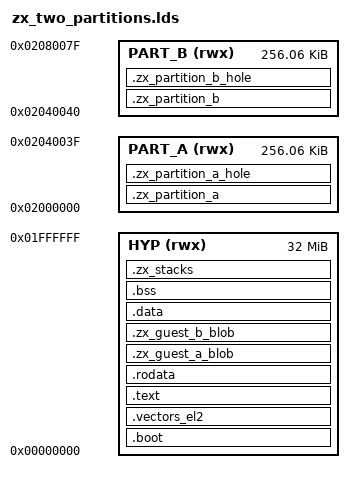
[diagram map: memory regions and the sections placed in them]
/***************************************************************************
 * Copyright (c) 2026 Eclipse ThreadX contributors
 *
 * This program and the accompanying materials are made available under the
 * terms of the MIT License which is available at
 * https://opensource.org/licenses/MIT.
 *
 * AI Disclosure: This file was largely AI-generated by Claude Code (Opus 5).
 * The AI-generated portions may be considered public domain (CC0-1.0)
 * and not subject to the project's licence. The human contributor has
 * reviewed and verified that the code is correct.
 *
 * SPDX-License-Identifier: MIT and CC0-1.0
 **************************************************************************/

/* Link map for the ZoneX TWO-PARTITION image on the Armv8-R AEM FVP.
 *
 * WHY THIS IS A THIRD SCRIPT AND NOT AN EXTENSION OF THE OTHER TWO
 *
 * The three images describe genuinely different memory.  The stage-2 probe
 * has two small windows and a relocatable blob copied into both; the
 * one-partition image has a single 256 KB window and embeds one guest; this
 * one has TWO 256 KB windows and embeds two, because a guest is linked for
 * its window and two windows are two different sets of bytes.
 *
 * Sharing one script would mean an image carrying a KEEP for a section it
 * never supplies -- which produces an EMPTY section rather than an error,
 * silently, at whatever address the location counter held.  That is the exact
 * failure the loader's magic-number check exists to catch, and the right
 * place to avoid it is here.
 *
 * THE WINDOW ADDRESSES ARE A CONTRACT, NOT A CHOICE.  Each is passed to its
 * guest's build from examples/fvp_baser_aemv8r/CMakeLists.txt, which is the
 * one place they are written down, and each guest declares what it was built
 * for in its own image header so that a mismatch is REFUSED at boot rather
 * than discovered as a fault at a plausible-looking address.  The numbers
 * below have to agree with that file, and the ASSERTs at the foot of this
 * script are what say so.
 *
 * THE UNGRANTED GRANULE BETWEEN THE TWO WINDOWS IS LOAD-BEARING.  Sixty-four
 * bytes belonging to nobody sit immediately after partition A and
 * immediately before partition B.  A region limit one granule too generous
 * at either end reaches into it, and an access there must fault -- which is
 * why partition B's base is not a round number.  An ungranted address far
 * from every grant proves only that unmapped memory faults; adjacency is
 * what makes it a boundary test.
 *
 * A NOTE ON ALIGN, because the two spellings are not equivalent
 *
 * Every ALIGN below is written AFTER the colon, which is the section's
 * ALIGNMENT.  Written before the colon it is the section's ADDRESS,
 * evaluated from a location counter that starts at zero, and it silently
 * overrides the region assignment.  Harmless where memory starts at zero and
 * catastrophic where it does not -- which is what makes it worth repeating
 * in every script here rather than in one of them.
 *
 * ZoneX's OWN code, data, bss and stack are covered by no region at all.
 * That is decision D2: with HSCTLR.BR=1 EL2's own accesses fall back to the
 * background map, while EL0/EL1 accesses that hit no region fault regardless
 * of BR -- so the hypervisor costs no region and is protected from the guest
 * precisely by not being mapped.
 */

ENTRY(_start)

__zx_hyp_stack_size = 0x1000;

/* THE PARTITION WINDOWS.  Each pair is passed to its guest's build from this
   board's CMakeLists.txt, and checked at boot against the guest's own image
   header.  */

__zx_partition_a_base = 0x02000000;
__zx_partition_a_size = 0x00040000;
__zx_partition_b_base = 0x02040040;
__zx_partition_b_size = 0x00040000;

MEMORY
{
    /* Two regions rather than one location counter, so that the window's
       address is declared rather than arrived at.  A script that reached
       0x02000000 by assignment would place the window correctly today and
       silently move it the first time the hypervisor's own image grew past
       32 MB -- which is a change nobody would connect to a guest that
       stopped working.  */

    HYP    (rwx) : ORIGIN = 0x00000000, LENGTH = 0x02000000    /* 32 MB    */
    PART_A (rwx) : ORIGIN = 0x02000000, LENGTH = 0x00040040    /* + a hole */
    PART_B (rwx) : ORIGIN = 0x02040040, LENGTH = 0x00040040    /* + a hole */
}

SECTIONS
{
    . = ALIGN(64);

    .boot :
    {
        KEEP(*(.text.boot))
    } > HYP

    .vectors_el2 :
    {
        KEEP(*(.vectors_el2))
    } > HYP

    .text :
    {
        *(.text*)
        *(.glue_7)
        *(.glue_7t)
    } > HYP

    .rodata :
    {
        . = ALIGN(4);
        *(.rodata*)
        . = ALIGN(4);
    } > HYP

    /* ------------------------------------------------------------------
       THE GUEST IMAGE, in the hypervisor's own memory.

       Covered by no stage-2 region, exactly like the rest of ZoneX, so a
       running partition cannot read the image it was loaded from -- which
       matters more than it looks: a partition able to read its own source
       image could also read the NEXT partition's, and the isolation claim
       would be about the copies rather than about the originals.
       ------------------------------------------------------------------ */

    .zx_guest_a_blob : ALIGN(64)
    {
        __zx_guest_a_blob_start = .;
        KEEP(*(.zx_guest_a_blob))
        . = ALIGN(4);
        __zx_guest_a_blob_end = .;
    } > HYP

    .zx_guest_b_blob : ALIGN(64)
    {
        __zx_guest_b_blob_start = .;
        KEEP(*(.zx_guest_b_blob))
        . = ALIGN(4);
        __zx_guest_b_blob_end = .;
    } > HYP

    .data : ALIGN(64)
    {
        __zx_data_start = .;
        *(.data*)
        . = ALIGN(4);
        __zx_data_end = .;
    } > HYP

    .bss (NOLOAD) : ALIGN(64)
    {
        __zx_bss_start = .;
        *(.bss*)
        *(COMMON)
        . = ALIGN(4);
        __zx_bss_end = .;
    } > HYP

    /* SP must stay 8-byte aligned (AAPCS), so the area is aligned before
       its top symbol is taken.  */

    .zx_stacks (NOLOAD) :
    {
        . = ALIGN(8);
        . = . + __zx_hyp_stack_size;
        __zx_hyp_stack_top = .;
    } > HYP

    . = ALIGN(8);
    _end = .;
    PROVIDE(end = .);

    /* ------------------------------------------------------------------
       PARTITION A'S WINDOW, and the ungranted granule after it.

       NOLOAD: there is nothing in this ELF to load here.  The contents
       arrive at run time, when the loader copies the guest image in, which
       is the path a real guest takes and the reason the manifest's
       image_start and image_end are load-bearing rather than decorative.

       THE HOLE IS ADJACENT BY CONSTRUCTION and the ASSERT keeps it that
       way.  An ungranted address far from every grant proves only that
       unmapped memory faults; the defect class worth catching is a region
       whose limit is out by ONE GRANULE, and only an adjacent hole catches
       it.
       ------------------------------------------------------------------ */

    .zx_partition_a (NOLOAD) : ALIGN(64)
    {
        __zx_partition_a_start = .;
        . = . + __zx_partition_a_size;
        __zx_partition_a_end = .;
    } > PART_A

    .zx_partition_a_hole (NOLOAD) : ALIGN(64)
    {
        __zx_partition_a_hole_start = .;
        . = . + 64;
        __zx_partition_a_hole_end = .;
    } > PART_A

    /* ------------------------------------------------------------------
       PARTITION B'S WINDOW, and its own ungranted granule.

       B's base is A's hole's END, so the sixty-four bytes between them
       belong to neither partition and are adjacent to both.  That single
       granule is what catches a limit one granule too generous at EITHER
       end -- the defect class that otherwise reads as a working system,
       because two region sets a whole kilobyte apart would pass a test
       that only checked the neighbour's data.
       ------------------------------------------------------------------ */

    .zx_partition_b (NOLOAD) : ALIGN(64)
    {
        __zx_partition_b_start = .;
        . = . + __zx_partition_b_size;
        __zx_partition_b_end = .;
    } > PART_B

    .zx_partition_b_hole (NOLOAD) : ALIGN(64)
    {
        __zx_partition_b_hole_start = .;
        . = . + 64;
        __zx_partition_b_hole_end = .;
    } > PART_B

    /* ------------------------------------------------------------------
       Assert the geometry the region programming and the loader depend on,
       so that a layout mistake fails the LINK rather than the run.  A
       region whose base is under-aligned does not fault: its low bits land
       on SH, AP and XN and silently change what it grants, which is the
       single hardest failure in this architecture to see.
       ------------------------------------------------------------------ */

    ASSERT((__zx_partition_a_start & 63) == 0,
           "partition A's window base is not 64-byte aligned")
    ASSERT((__zx_partition_a_end & 63) == 0,
           "partition A's window is not a whole number of granules")
    ASSERT(__zx_partition_a_start == __zx_partition_a_base,
           "partition A's window is not at the address the guest was linked for")
    ASSERT(__zx_partition_a_hole_start == __zx_partition_a_end,
           "the ungranted granule is NOT adjacent to partition A's window")

    ASSERT((__zx_partition_b_start & 63) == 0,
           "partition B's window base is not 64-byte aligned")
    ASSERT(((__zx_partition_b_end - __zx_partition_b_start) & 63) == 0,
           "partition B's window is not a whole number of granules")
    ASSERT(__zx_partition_b_start == __zx_partition_b_base,
           "partition B's window is not at the address its guest was linked for")
    ASSERT(__zx_partition_b_hole_start == __zx_partition_b_end,
           "the ungranted granule is NOT adjacent to partition B's window")

    /* AND THE GRANULE BETWEEN THEM BELONGS TO NOBODY.  A's hole ends
       exactly where B's window begins, so there is one ungranted granule
       and it is adjacent to both windows.  Written as an assert rather than
       trusted to the MEMORY lengths, because the two are computed from
       different numbers and a change to either would break this silently.  */

    ASSERT(__zx_partition_a_hole_end == __zx_partition_b_start,
           "the ungranted granule is not adjacent to both partition windows")

    /* And the two windows do not overlap, which PMSAv8-R makes worse than a
       logical error: two enabled regions matching one address is CONSTRAINED
       UNPREDICTABLE, and it aborts on the S32Z280.  The manifest validator
       refuses it too; this catches it a whole build earlier.  */

    ASSERT(__zx_partition_a_end <= __zx_partition_b_start,
           "the two partition windows overlap")

    ASSERT((__zx_guest_a_blob_start & 63) == 0,
           "guest A's image is not 64-byte aligned")
    ASSERT((__zx_guest_b_blob_start & 63) == 0,
           "guest B's image is not 64-byte aligned")

    /* THE BLOB IS NOT EMPTY, and this is the check that catches an .incbin
       whose file was missing or a linker input pattern that matched
       nothing.  Asserted against the END OF THE IMAGE HEADER rather than
       against zero, because a blob too small to carry its own header is
       just as useless as one of no size at all -- and the loader's magic
       check would then be reading past the end of the section, which is
       the out-of-bounds read this assert exists to prevent.

       0x90 is ZX_GUEST_IMAGE_OFF_MAGIC + 4, from
       examples/common/zx_guest_abi.h.  A linker script cannot include a C
       header, so the number is restated here -- and it is restated WRONG
       the moment the header moves, which is exactly what happened when the
       mailbox grew to two granules and pushed the entry branch and the
       header from 0x40 to 0x80.  The bound stayed at 0x50, so a blob of
       0x51 to 0x8F bytes linked cleanly and the magic check read past the
       section into whatever followed it.  */

    ASSERT((__zx_guest_a_blob_end - __zx_guest_a_blob_start) >= 0x90,
           "guest A's embedded image is empty or too small to carry its header")
    ASSERT((__zx_guest_b_blob_end - __zx_guest_b_blob_start) >= 0x90,
           "guest B's embedded image is empty or too small to carry its header")

    ASSERT((__zx_guest_a_blob_end - __zx_guest_a_blob_start)
               <= __zx_partition_a_size,
           "guest A's embedded image does not fit partition A's window")
    ASSERT((__zx_guest_b_blob_end - __zx_guest_b_blob_start)
               <= __zx_partition_b_size,
           "guest B's embedded image does not fit partition B's window")

    /* And the hypervisor's own image must not have reached the window.  The
       two MEMORY regions make this impossible rather than merely unlikely,
       so this asserts the thing the reader would otherwise have to work out
       from the region lengths.  */

    ASSERT(_end <= __zx_partition_a_base,
           "the hypervisor's own image has grown into partition A's window")
}
